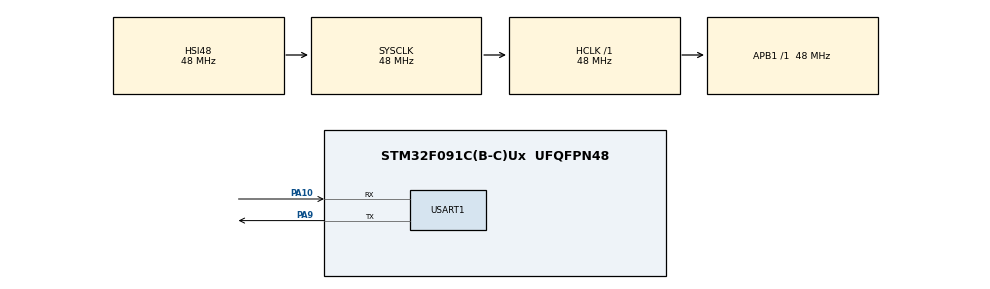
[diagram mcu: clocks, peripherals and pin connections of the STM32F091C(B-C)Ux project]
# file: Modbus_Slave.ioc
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Dma.Request0=USART1_RX
Dma.Request1=USART1_TX
Dma.USART1_RX.0.Direction=DMA_PERIPH_TO_MEMORY
Dma.USART1_RX.0.Instance=DMA1_Channel1
Dma.USART1_RX.0.MemDataAlignment=DMA_MDATAALIGN_BYTE
Dma.USART1_RX.0.MemInc=DMA_MINC_ENABLE
Dma.USART1_RX.0.Mode=DMA_NORMAL
Dma.USART1_RX.0.PeriphDataAlignment=DMA_PDATAALIGN_BYTE
Dma.USART1_RX.0.PeriphInc=DMA_PINC_DISABLE
Dma.USART1_RX.0.Priority=DMA_PRIORITY_LOW
Dma.USART1_TX.1.Direction=DMA_MEMORY_TO_PERIPH
Dma.USART1_TX.1.Instance=DMA1_Channel2
Dma.USART1_TX.1.MemDataAlignment=DMA_MDATAALIGN_BYTE
Dma.USART1_TX.1.MemInc=DMA_MINC_ENABLE
Dma.USART1_TX.1.Mode=DMA_NORMAL
Dma.USART1_TX.1.PeriphDataAlignment=DMA_PDATAALIGN_BYTE
Dma.USART1_TX.1.PeriphInc=DMA_PINC_DISABLE
Dma.USART1_TX.1.Priority=DMA_PRIORITY_LOW
Mcu.Family=STM32F0
Mcu.Name=STM32F091C(B-C)Ux
Mcu.Package=UFQFPN48
NVIC.DMA1_Ch1_IRQn=true\:0\:0\:false\:false\:true\:false\:true\:true
NVIC.DMA1_Ch2_3_DMA2_Ch1_2_IRQn=true\:0\:0\:false\:false\:true\:false\:true\:true
NVIC.TIM14_IRQn=true\:0\:0\:false\:false\:true\:true\:true\:true
NVIC.TIM16_IRQn=true\:0\:0\:false\:false\:true\:true\:true\:true
NVIC.USART1_IRQn=true\:0\:0\:false\:false\:true\:true\:true\:true
PA10.Mode=Asynchronous
PA10.Signal=USART1_RX
PA9.Mode=Asynchronous
PA9.Signal=USART1_TX
ProjectManager.HeapSize=0x200
ProjectManager.StackSize=0x400
ProjectManager.TargetToolchain=STM32CubeIDE
RCC.AHBFreq_Value=48000000
RCC.APB1Freq_Value=48000000
RCC.APB1TimFreq_Value=48000000
RCC.HCLKFreq_Value=48000000
RCC.SYSCLKFreq_VALUE=48000000
RCC.SYSCLKSource=RCC_SYSCLKSOURCE_HSI48
TIM14.Period=0
TIM14.Prescaler=2399
TIM16.Period=1999
TIM16.Prescaler=47
USART1.VirtualMode-Asynchronous=VM_ASYNC
VP_TIM14_VS_ClockSourceINT.Mode=Enable_Timer
VP_TIM16_VS_ClockSourceINT.Mode=Enable_Timer
board=custom

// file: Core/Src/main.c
/* USER CODE BEGIN Header */
/**
  ******************************************************************************
  * @file           : main.c
  * @brief          : Main program body
  ******************************************************************************
  * @attention
  *
  * Copyright (c) 2024 STMicroelectronics.
  * All rights reserved.
  *
  * This software is licensed under terms that can be found in the LICENSE file
  * in the root directory of this software component.
  * If no LICENSE file comes with this software, it is provided AS-IS.
  *
  ******************************************************************************
  */
/* USER CODE END Header */
#include "main.h"
#include "dma.h"
#include "tim.h"
#include "usart.h"
#include "gpio.h"

/* USER CODE BEGIN Includes */
#include "mb.h"
#include "mb_API.h"
#include "port.h"
#include "mb_slave_API.h"
/* USER CODE END Includes */

void SystemClock_Config(void);

uint16_t qq[10] ;
int main(void)
{

  /* MCU Configuration--------------------------------------------------------*/
  HAL_Init();

  /* Configure the system clock */
  SystemClock_Config();

  /* Initialize all configured peripherals */
  MX_GPIO_Init();
  MX_DMA_Init();
  MX_TIM14_Init();
  MX_TIM16_Init();
  MX_USART1_UART_Init();
	/* USER CODE BEGIN 2 */
	MbSlaveMode(MB_RTU, MB_SLAVE_ADDRESS, PORT, BAUD_RATE, MB_PAR_NONE);
	/* USER CODE END 2 */

	/* Infinite loop */
  while (1)
  {

	}
}

void SystemClock_Config(void)
{
  RCC_OscInitTypeDef RCC_OscInitStruct = {0};
  RCC_ClkInitTypeDef RCC_ClkInitStruct = {0};
  RCC_PeriphCLKInitTypeDef PeriphClkInit = {0};

  /** Initializes the RCC Oscillators according to the specified parameters
  * in the RCC_OscInitTypeDef structure.
  */
  RCC_OscInitStruct.OscillatorType = RCC_OSCILLATORTYPE_HSI48;
  RCC_OscInitStruct.HSI48State = RCC_HSI48_ON;
  RCC_OscInitStruct.PLL.PLLState = RCC_PLL_NONE;
  if (HAL_RCC_OscConfig(&RCC_OscInitStruct) != HAL_OK)
  {
    Error_Handler();
  }

  /** Initializes the CPU, AHB and APB buses clocks
  */
  RCC_ClkInitStruct.ClockType = RCC_CLOCKTYPE_HCLK|RCC_CLOCKTYPE_SYSCLK
                              |RCC_CLOCKTYPE_PCLK1;
  RCC_ClkInitStruct.SYSCLKSource = RCC_SYSCLKSOURCE_HSI48;
  RCC_ClkInitStruct.AHBCLKDivider = RCC_SYSCLK_DIV1;
  RCC_ClkInitStruct.APB1CLKDivider = RCC_HCLK_DIV1;

  if (HAL_RCC_ClockConfig(&RCC_ClkInitStruct, FLASH_LATENCY_1) != HAL_OK)
  {
    Error_Handler();
  }
  PeriphClkInit.PeriphClockSelection = RCC_PERIPHCLK_USART1;
  PeriphClkInit.Usart1ClockSelection = RCC_USART1CLKSOURCE_PCLK1;
  if (HAL_RCCEx_PeriphCLKConfig(&PeriphClkInit) != HAL_OK)
  {
    Error_Handler();
  }
}

void Error_Handler(void)
{
  __disable_irq();
  while (1)
  {
  }
}
